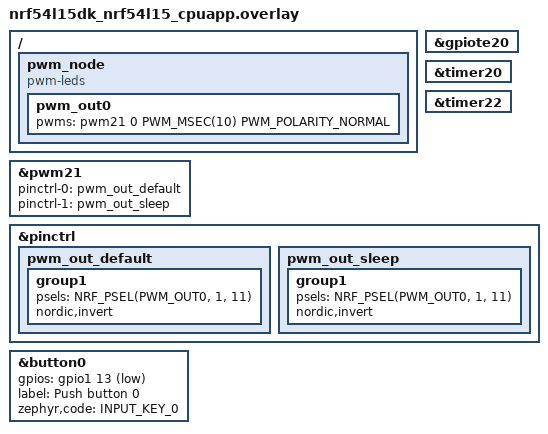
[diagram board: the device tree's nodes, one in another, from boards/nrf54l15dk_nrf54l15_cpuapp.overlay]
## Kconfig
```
#
# Copyright (c) 2018 Nordic Semiconductor
#
# SPDX-License-Identifier: LicenseRef-Nordic-5-Clause
#

source "Kconfig.zephyr"

menu "Lesson 5 Exercise 2 config"

config PWM_DUTY_CYCLE
	depends on  PWM || NRFX_PWM_GRTC
	int "PWM duty cycle in %"
	default 25

config NRFX_PWM_GRTC
	bool "Use GRTC for PWM"
	default n

config NRFX_TIMER00_1MHz
	bool "Use TIMER00 at 1MHz"
	default n
	select NRFX_TIMER

config NRFX_TIMER00_128MHz
	bool "Use TIMER00 at 128MHz"
	default n
	select NRFX_TIMER

config NRFX_TIMER20_1MHz
	bool "Use TIMER20 at 1MHz"
	default n
	select NRFX_TIMER

endmenu
```

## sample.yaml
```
sample:
  description: Designing Low Power Bluetooth LE devices Lesson 5 Exercise 2 - Peripherals
  name: Low Power Bluetooth LE devices - Lesson 5 Exercise 2 

common: 
    sysbuild: true
    build_only: true
    sysbuild: true

    integration_platforms:
      - nrf54l15dk/nrf54l15/cpuapp
      - nrf54l15dk/nrf54l10/cpuapp
      - nrf54l15dk/nrf54l05/cpuapp
      - nrf54lm20dk/nrf54lm20a/cpuapp
      - nrf54lm20dk/nrf54lm20b/cpuapp
      - nrf54ls05dk/nrf54ls05a/cpuapp
      - nrf54ls05dk/nrf54ls05b/cpuapp
    platform_allow:
      - nrf54l15dk/nrf54l15/cpuapp
      - nrf54l15dk/nrf54l10/cpuapp
      - nrf54l15dk/nrf54l05/cpuapp
      - nrf54lm20dk/nrf54lm20a/cpuapp
      - nrf54lm20dk/nrf54lm20b/cpuapp
      - nrf54ls05dk/nrf54ls05a/cpuapp
      - nrf54ls05dk/nrf54ls05b/cpuapp

tests:
  l5.e2.sol: {} 
  
```

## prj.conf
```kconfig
CONFIG_GPIO=y
CONFIG_NRFX_GPPI=y
CONFIG_NRFX_TIMER=y
CONFIG_PM_DEVICE=y

CONFIG_PWM=y

CONFIG_SERIAL=n
CONFIG_CONSOLE=n
CONFIG_UART_CONSOLE=n

# STEP 2.1 - Enable system timer to trigger pattern
# STEP 3.2 - Disable system timer as the pattern trigger
CONFIG_USE_TIMER_TRIGGER=n

# STEP 3.1 - Enable DPPI connection
# STEP 4.6 - Disable DPPI connection
CONFIG_USE_PPI_WORKFLOW=n
 
# STEP 4.1 - Configure the PWM period
CONFIG_PWM_OUTPUT_PERIOD_US=100

# STEP 4.2 - Configure pattern period
CONFIG_GPIO_EVENT_PERIOD_US=10

# STEP 4.3 - Increase the number of events in the pattern
CONFIG_GPIO_EVENTS_CNT=6

 
```

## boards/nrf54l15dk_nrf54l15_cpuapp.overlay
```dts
&gpiote20 {
    status = "okay";
};

&timer20 {
    status = "okay";
};

&timer22 {
    status = "okay";
};

&pwm21 {
    status = "okay";
    pinctrl-0 = <&pwm_out_default>;
    pinctrl-1 = <&pwm_out_sleep>;
    pinctrl-names = "default", "sleep";
};

&pinctrl {
    pwm_out_default: pwm_out_default {
        group1 {
            psels = <NRF_PSEL(PWM_OUT0, 1, 11)>;
            nordic,invert;
        };
    };

    pwm_out_sleep: pwm_out_sleep {
        group1 {
            psels = <NRF_PSEL(PWM_OUT0, 1, 11)>;
            nordic,invert;
        };
    };
};

//STEP 2.3 Disable internal pull-up on button 0
&button0 {
    // Default button0 GPIO configuration
    // gpios = <&gpio1 13 (GPIO_PULL_UP | GPIO_ACTIVE_LOW)>;
    gpios = <&gpio1 13 ( GPIO_ACTIVE_LOW)>;
    label = "Push button 0";
    zephyr,code = <INPUT_KEY_0>;
};

/ { pwm_node: pwm_node{
        compatible = "pwm-leds";
        pwm_out0: pwm_out0 {
            pwms = <&pwm21 0 PWM_MSEC(10) PWM_POLARITY_NORMAL>;
        };
    };
};
```

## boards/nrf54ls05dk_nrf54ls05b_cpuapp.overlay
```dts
&gpiote20 {
    status = "okay";
};

&timer20 {
    status = "okay";
};

&timer00 {
    status = "okay";
};

&pwm20 {
    status = "okay";
    pinctrl-0 = <&pwm_out_default>;
    pinctrl-1 = <&pwm_out_sleep>;
    pinctrl-names = "default", "sleep";
};

&pinctrl {
    pwm_out_default: pwm_out_default {
        group1 {
            psels = <NRF_PSEL(PWM_OUT0, 1, 10)>;
            nordic,invert;
        };
    };

    pwm_out_sleep: pwm_out_sleep {
        group1 {
            psels = <NRF_PSEL(PWM_OUT0, 1, 10)>;
            nordic,invert;
        };
    };
};

//STEP 2.3 Disable internal pull-up on button 0
&button0 {
    gpios = <&gpio1 13 ( GPIO_ACTIVE_LOW)>;
    label = "Push button 0";
    zephyr,code = <INPUT_KEY_0>;
};

/ { pwm_node: pwm_node{
        compatible = "pwm-leds";
        pwm_out0: pwm_out0 {
            pwms = <&pwm20 0 PWM_MSEC(10) PWM_POLARITY_NORMAL>;
        };
    };
};
```

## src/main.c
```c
/*
 * Copyright (c) 2018 Nordic Semiconductor ASA
 *
 * SPDX-License-Identifier: LicenseRef-Nordic-5-Clause
 */

#include <zephyr/types.h>
#include <stddef.h>
#include <string.h>
#include <errno.h>
#include <zephyr/sys/printk.h>
#include <zephyr/sys/byteorder.h>
#include <zephyr/kernel.h>

#include <zephyr/device.h>
#include <zephyr/drivers/gpio.h>
#include <soc.h>

#include <zephyr/bluetooth/bluetooth.h>
#include <zephyr/bluetooth/hci.h>
#include <zephyr/bluetooth/conn.h>
#include <zephyr/bluetooth/uuid.h>
#include <zephyr/bluetooth/gatt.h>

#include <bluetooth/services/lbs.h>
#include <zephyr/settings/settings.h>
#include <helpers.h>


#define DEVICE_NAME             CONFIG_BT_DEVICE_NAME
#define DEVICE_NAME_LEN         (sizeof(DEVICE_NAME) - 1)

#define RANDOM_BYTES_COUNT      16

#define RUN_STATUS_LED          DK_LED1
#define CON_STATUS_LED          DK_LED2
#define RUN_LED_BLINK_INTERVAL  1000

#define USER_LED                DK_LED3

#define USER_BUTTON             DK_BTN1_MSK

#define BT_LE_ADV_CONN_1000                                                                      \
    BT_LE_ADV_PARAM(BT_LE_ADV_OPT_CONN, BT_GAP_ADV_SLOW_INT_MIN, BT_GAP_ADV_SLOW_INT_MIN,  \
            NULL)

static bool app_button_state;
static struct k_work adv_work;

static const struct bt_data ad[] = {
    BT_DATA_BYTES(BT_DATA_FLAGS, (BT_LE_AD_GENERAL | BT_LE_AD_NO_BREDR)),
    BT_DATA(BT_DATA_NAME_COMPLETE, DEVICE_NAME, DEVICE_NAME_LEN),
};

static const struct bt_data sd[] = {
    BT_DATA_BYTES(BT_DATA_UUID128_ALL, BT_UUID_LBS_VAL),
};

static void adv_work_handler(struct k_work *work)
{
    int err = bt_le_adv_start(BT_LE_ADV_CONN_1000, ad, ARRAY_SIZE(ad), sd, ARRAY_SIZE(sd));

    if (err) {
        printk("Advertising failed to start (err %d)\n", err);
        return;
    }

    printk("Advertising successfully started\n");
}

static void advertising_start(void)
{
    k_work_submit(&adv_work);
}

static void connected(struct bt_conn *conn, uint8_t err)
{
    if (err) {
        printk("Connection failed, err 0x%02x %s\n", err, bt_hci_err_to_str(err));
        return;
    }

    printk("Connected\n");
}

static void disconnected(struct bt_conn *conn, uint8_t reason)
{
    printk("Disconnected, reason 0x%02x %s\n", reason, bt_hci_err_to_str(reason));
}


static void recycled_cb(void)
{
    printk("Connection object available from previous conn. Disconnect is complete!\n");
    advertising_start();
}

BT_CONN_CB_DEFINE(conn_callbacks) = {
    .connected        = connected,
    .disconnected     = disconnected,
    .recycled         = recycled_cb,
};

static void app_led_cb(bool led_state)
{
    (void) led_state;
}

static bool app_button_cb(void)
{
    return app_button_state;
}

static struct bt_lbs_cb lbs_callbacs = {
    .led_cb    = app_led_cb,
    .button_cb = app_button_cb,
};


int main(void)
{
    int err;

    printk("Starting Bluetooth Peripheral LBS sample\n");

    err = bt_enable(NULL);
    if (err) {
        printk("Bluetooth init failed (err %d)\n", err);
        return 0;
    }

    printk("Bluetooth initialized\n");

    err = bt_lbs_init(&lbs_callbacs);
    if (err) {
        printk("Failed to init LBS (err:%d)\n", err);
        return 0;
    }

    k_work_init(&adv_work, adv_work_handler);
    advertising_start();

    #if CONFIG_WATCHDOG
        if( init_watchdog() <0) {
            printk("Failed to initialize watchdog \n");
            return 0;
        }
    #endif

    #if defined(CONFIG_NRFX_TIMER00_1MHz)
        enable_timer00(TIMER_1MHZ);
    #endif

    #if defined(CONFIG_NRFX_TIMER00_128MHz)
        enable_timer00(TIMER_128MHZ);
    #endif

    #if defined(CONFIG_NRFX_TIMER20_1MHz)
        enable_timer20(TIMER_1MHZ);
    #endif

    #if defined(CONFIG_NRFX_PWM_GRTC)   
        set_grtc_pwm(CONFIG_PWM_DUTY_CYCLE);   
    #endif    

    #if defined(CONFIG_PWM) 
    if ( set_pwm_out(CONFIG_PWM_DUTY_CYCLE ) < 0) {
        printk("Failed to set PWM output \n");
        return 0;
    }
    #endif

    while (1) 
    {
        #if defined(CONFIG_WATCHDOG)
           watchdog_feed();
        #endif
            k_sleep(K_MSEC(1000));
    }
}
```
